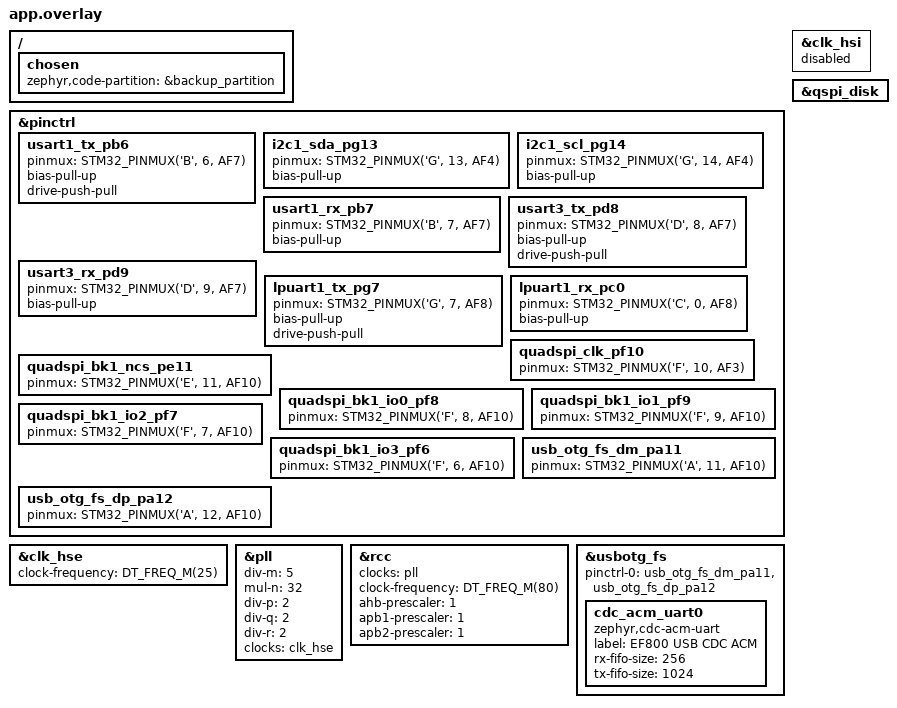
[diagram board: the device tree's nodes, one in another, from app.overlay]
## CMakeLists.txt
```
# SPDX-License-Identifier: Apache-2.0
cmake_minimum_required(VERSION 3.28.0)

set(BOARD_ROOT ${CMAKE_CURRENT_LIST_DIR}/../..)
set(DTS_ROOT ${CMAKE_CURRENT_LIST_DIR}/../..)
find_package(Zephyr REQUIRED HINTS $ENV{ZEPHYR_BASE})
project(ef800_backup)

target_sources(app PRIVATE
	src/main.c
	src/ef800_backup_composition.c
	src/ef800_backup_usb_mtp.c
	${CMAKE_CURRENT_LIST_DIR}/../../shared/ef800_composition/ef800_composition.c
	${CMAKE_CURRENT_LIST_DIR}/../../shared/ef800_persistence/ef800_persistence.c
	${CMAKE_CURRENT_LIST_DIR}/../../shared/ef800_watchdog/ef800_watchdog.c
	${CMAKE_CURRENT_LIST_DIR}/../../shared/ef800_storage/ef800_qspi_layout.c
	${CMAKE_CURRENT_LIST_DIR}/../../shared/ef800_lcd_contrast/ef800_lcd_contrast.c
	${CMAKE_CURRENT_LIST_DIR}/../../shared/ef800_lcd_contrast/ef800_lcd_contrast_storage.c
	${CMAKE_CURRENT_LIST_DIR}/../../shared/ef800_lcd_contrast/ef800_lcd_contrast_stm32.c
	${CMAKE_CURRENT_LIST_DIR}/../../shared/ef800_ports/ef800_console.c
	${CMAKE_CURRENT_LIST_DIR}/../../shared/ef800_ports/ef800_log_backend.c
	${CMAKE_CURRENT_LIST_DIR}/../../shared/ef800_update/ef800_update.c
)

target_include_directories(app PRIVATE
	${CMAKE_CURRENT_LIST_DIR}/../../shared/ef800_watchdog
	${CMAKE_CURRENT_LIST_DIR}/../../shared/ef800_ports
	${CMAKE_CURRENT_LIST_DIR}/../../shared/ef800_update
	${CMAKE_CURRENT_LIST_DIR}/../../shared/ef800_measurement
	${CMAKE_CURRENT_LIST_DIR}/../../shared/ef800_storage
	${CMAKE_CURRENT_LIST_DIR}/../../shared/ef800_lcd_contrast
	${CMAKE_CURRENT_LIST_DIR}/../../shared/ef800_composition
	${CMAKE_CURRENT_LIST_DIR}/../../shared/ef800_persistence
	${CMAKE_CURRENT_LIST_DIR}/src
)

target_include_directories(app PRIVATE
)
```

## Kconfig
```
# SPDX-License-Identifier: Apache-2.0

menu "EF800 backup recovery"

config EF800_USB_VID
	hex "Recovery USB vendor ID"
	default 0x2fe3
	help
	  Replace the development VID with the product VID before production.

config EF800_USB_PID
	hex "Recovery USB product ID"
	default 0xef80
	help
	  Product-specific PID for the EF800 recovery MTP device.

config EF800_USB_SELF_POWERED
	bool "Mark the recovery USB device as self-powered"
	default y
	help
	  Set the USB configuration self-powered attribute when the hardware is
	  powered independently of USB VBUS.

endmenu

source "Kconfig.zephyr"
```

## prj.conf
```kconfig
# SPDX-License-Identifier: Apache-2.0
CONFIG_FLASH=y
CONFIG_FLASH_MAP=y
CONFIG_FLASH_PAGE_LAYOUT=y
CONFIG_PINCTRL=y
CONFIG_GPIO=y
CONFIG_CLOCK_CONTROL=y
CONFIG_RESET=y
CONFIG_SERIAL=y
CONFIG_UART_USE_RUNTIME_CONFIGURE=y
CONFIG_LOG=y
CONFIG_LOG_BACKEND_UART=n
CONFIG_LOG_MODE_IMMEDIATE=y
CONFIG_WATCHDOG=y
CONFIG_IWDG_STM32_INITIAL_TIMEOUT=10000
CONFIG_DISK_DRIVERS=y
CONFIG_DISK_DRIVER_FLASH=y
CONFIG_FILE_SYSTEM=y
CONFIG_FAT_FILESYSTEM_ELM=y

CONFIG_USB_DEVICE_STACK_NEXT=y
CONFIG_USBD_MTP_CLASS=y
CONFIG_USBD_MTP_MAX_HANDLES=12
CONFIG_USBD_MTP_STORAGES_PER_INSTANCE=4
CONFIG_USBD_THREAD_STACK_SIZE=4096

CONFIG_EF800_USB_VID=0x2fe3
CONFIG_EF800_USB_PID=0xef80
# Recovery mode must remain within the expanded 128 KiB backup partition.
CONFIG_MAIN_STACK_SIZE=2048

# The recovery image occupies the fixed backup partition selected by app.overlay.
CONFIG_USE_DT_CODE_PARTITION=y
```

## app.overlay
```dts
/* SPDX-License-Identifier: Apache-2.0 */

/ {
	chosen {
		zephyr,code-partition = &backup_partition;
	};
};

#include <zephyr/dt-bindings/pinctrl/stm32-pinctrl.h>

&pinctrl {
	usart1_tx_pb6: usart1_tx_pb6 {
		pinmux = <STM32_PINMUX('B', 6, AF7)>;
		bias-pull-up;
		drive-push-pull;
	};

	i2c1_sda_pg13: i2c1_sda_pg13 {
		pinmux = <STM32_PINMUX('G', 13, AF4)>;
		bias-pull-up;
	};

	i2c1_scl_pg14: i2c1_scl_pg14 {
		pinmux = <STM32_PINMUX('G', 14, AF4)>;
		bias-pull-up;
	};

	usart1_rx_pb7: usart1_rx_pb7 {
		pinmux = <STM32_PINMUX('B', 7, AF7)>;
		bias-pull-up;
	};

	usart3_tx_pd8: usart3_tx_pd8 {
		pinmux = <STM32_PINMUX('D', 8, AF7)>;
		bias-pull-up;
		drive-push-pull;
	};

	usart3_rx_pd9: usart3_rx_pd9 {
		pinmux = <STM32_PINMUX('D', 9, AF7)>;
		bias-pull-up;
	};

	lpuart1_tx_pg7: lpuart1_tx_pg7 {
		pinmux = <STM32_PINMUX('G', 7, AF8)>;
		bias-pull-up;
		drive-push-pull;
	};

	lpuart1_rx_pc0: lpuart1_rx_pc0 {
		pinmux = <STM32_PINMUX('C', 0, AF8)>;
		bias-pull-up;
	};

	quadspi_clk_pf10: quadspi_clk_pf10 {
		pinmux = <STM32_PINMUX('F', 10, AF3)>;
	};

	quadspi_bk1_ncs_pe11: quadspi_bk1_ncs_pe11 {
		pinmux = <STM32_PINMUX('E', 11, AF10)>;
	};

	quadspi_bk1_io0_pf8: quadspi_bk1_io0_pf8 {
		pinmux = <STM32_PINMUX('F', 8, AF10)>;
	};

	quadspi_bk1_io1_pf9: quadspi_bk1_io1_pf9 {
		pinmux = <STM32_PINMUX('F', 9, AF10)>;
	};

	quadspi_bk1_io2_pf7: quadspi_bk1_io2_pf7 {
		pinmux = <STM32_PINMUX('F', 7, AF10)>;
	};

	quadspi_bk1_io3_pf6: quadspi_bk1_io3_pf6 {
		pinmux = <STM32_PINMUX('F', 6, AF10)>;
	};

	usb_otg_fs_dm_pa11: usb_otg_fs_dm_pa11 {
		pinmux = <STM32_PINMUX('A', 11, AF10)>;
	};

	usb_otg_fs_dp_pa12: usb_otg_fs_dp_pa12 {
		pinmux = <STM32_PINMUX('A', 12, AF10)>;
	};
};

&clk_hse {
	clock-frequency = <DT_FREQ_M(25)>;
	status = "okay";
};

&clk_hsi {
	status = "disabled";
};

&pll {
	div-m = <5>;
	mul-n = <32>;
	div-p = <2>;
	div-q = <2>;
	div-r = <2>;
	clocks = <&clk_hse>;
	status = "okay";
};

&rcc {
	clocks = <&pll>;
	clock-frequency = <DT_FREQ_M(80)>;
	ahb-prescaler = <1>;
	apb1-prescaler = <1>;
	apb2-prescaler = <1>;
};

&qspi_disk {
	status = "okay";
};

&usbotg_fs {
	pinctrl-0 = <&usb_otg_fs_dm_pa11 &usb_otg_fs_dp_pa12>;
	pinctrl-names = "default";
	status = "okay";

	cdc_acm_uart0: cdc_acm_uart0 {
		compatible = "zephyr,cdc-acm-uart";
		label = "EF800 USB CDC ACM";
		rx-fifo-size = <256>;
		tx-fifo-size = <1024>;
	};
};
```

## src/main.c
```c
/* SPDX-License-Identifier: Apache-2.0 */
/** @file @brief Run EF800 Backup recovery, storage, and USB services. */

#include <stdbool.h>
#include <errno.h>

#include <ff.h>
#include <zephyr/device.h>
#include <zephyr/devicetree.h>
#include <zephyr/fs/fs.h>
#include <zephyr/kernel.h>
#include <zephyr/logging/log.h>
#include <zephyr/storage/flash_map.h>

#include "ef800_watchdog.h"
#include "ef800_console.h"
#include "ef800_qspi_layout.h"
#include "ef800_backup_usb_mtp.h"
#include "ef800_backup_composition.h"
#include "ef800_lcd_contrast.h"
#include "ef800_lcd_contrast_storage.h"
#include "ef800_lcd_contrast_stm32.h"

LOG_MODULE_REGISTER(ef800_backup, LOG_LEVEL_INF);

#define EF800_BACKUP_CONFIGURATION_MOUNT "/EF800:"
#define EF800_BACKUP_DATA_MOUNT "/DATA:"

static K_THREAD_STACK_DEFINE(watchdog_stack, 512);
static struct k_thread watchdog_thread;
static FATFS configuration_fat_fs;
static FATFS data_fat_fs;
static struct fs_mount_t configuration_mount = {
	.type = FS_FATFS,
	.mnt_point = EF800_BACKUP_CONFIGURATION_MOUNT,
	.fs_data = &configuration_fat_fs,
	.storage_dev = (void *)PARTITION_ID(qspi_configuration_partition),
	.flags = FS_MOUNT_FLAG_NO_FORMAT,
};
static struct fs_mount_t data_mount = {
	.type = FS_FATFS,
	.mnt_point = EF800_BACKUP_DATA_MOUNT,
	.fs_data = &data_fat_fs,
	.storage_dev = (void *)PARTITION_ID(qspi_storage_partition),
	.flags = FS_MOUNT_FLAG_NO_FORMAT,
};
static struct ef800_lcd_contrast lcd_contrast;

static int backup_contrast_set_pwm(void *context, uint8_t duty_percent)
{
	ARG_UNUSED(context);
	return ef800_lcd_contrast_stm32_set(duty_percent);
}

static void backup_contrast_diagnostic(void *context, const char *message,
				       int error)
{
	ARG_UNUSED(context);
	LOG_WRN("%s: %d", message, error);
}

static const struct ef800_lcd_contrast_ops backup_contrast_ops = {
	.load_duty = ef800_lcd_contrast_storage_load_duty,
	.save_duty = ef800_lcd_contrast_storage_save_duty,
	.set_pwm = backup_contrast_set_pwm,
	.diagnostic = backup_contrast_diagnostic,
};

static void backup_watchdog_task(void *arg1, void *arg2, void *arg3)
{
	ARG_UNUSED(arg1);
	ARG_UNUSED(arg2);
	ARG_UNUSED(arg3);

	while (true) {
		(void)ef800_watchdog_feed();
		k_msleep(250U);
	}
}

static void backup_watchdog_start(void)
{
	if (ef800_watchdog_start(1000U) != 0) {
		return;
	}
	(void)k_thread_create(&watchdog_thread, watchdog_stack,
				      K_THREAD_STACK_SIZEOF(watchdog_stack),
				      backup_watchdog_task, NULL, NULL, NULL,
				      K_PRIO_PREEMPT(2), 0, K_NO_WAIT);
}
#define EF800_USB_UDC_NODE DT_NODELABEL(usbotg_fs)

BUILD_ASSERT(DT_NODE_HAS_STATUS(EF800_USB_UDC_NODE, okay),
		     "EF800 recovery requires an enabled USB device controller");

static int ensure_directory(const char *path)
{
	struct fs_dirent entry;
	int ret = fs_stat(path, &entry);

	if (ret == 0) {
		return entry.type == FS_DIR_ENTRY_DIR ? 0 : -ENOTDIR;
	}
	ret = fs_mkdir(path);
	return ret == -EEXIST ? 0 : ret;
}

static int create_recovery_roots(void)
{
	static const char *const paths[] = {
		"/EF800:/.configuration",
		"/DATA:/data",
		"/DATA:/plugins",
		"/DATA:/fwu",
	};

	for (size_t index = 0U; index < ARRAY_SIZE(paths); ++index) {
		int ret = ensure_directory(paths[index]);

		if (ret != 0) {
			LOG_ERR("Cannot prepare MTP root %s: %d", paths[index], ret);
			return ret;
		}
	}
	return 0;
}

int main(void)
{
	const struct device *const udc = DEVICE_DT_GET(EF800_USB_UDC_NODE);
	const struct flash_area *boot_state_area;
	bool legacy_layout;
	bool configuration_mounted = false;
	bool data_mounted = false;
	int ret;

	(void)ef800_console_init(true);
	printk("ef800 backup application: console=%u\r\n",
	       ef800_console_get_target());
	backup_watchdog_start();

	if (!device_is_ready(udc)) {
		LOG_ERR("USB device controller unavailable; recovery MTP not started");
		goto wait;
	}
	ret = flash_area_open(PARTITION_ID(qspi_bootstate_partition),
		&boot_state_area);
	if (ret != 0) {
		LOG_ERR("Boot-state QSPI partition unavailable: %d", ret);
		goto wait;
	}
	ret = ef800_qspi_layout_check_legacy_area(boot_state_area, &legacy_layout);
	flash_area_close(boot_state_area);
	if (ret != 0 || legacy_layout) {
		LOG_ERR("Legacy or unavailable QSPI layout; recovery MTP not started: %d",
			ret != 0 ? ret : -ENOTSUP);
		goto wait;
	}
	ret = fs_mount(&configuration_mount);
	if (ret != 0) {
		LOG_ERR("Configuration FAT mount failed (no format attempted): %d", ret);
		goto wait;
	}
	configuration_mounted = true;
	ret = fs_mount(&data_mount);
	if (ret != 0) {
		LOG_ERR("Shared-data FAT mount failed (no format attempted): %d", ret);
		goto cleanup;
	}
	data_mounted = true;
	ret = create_recovery_roots();
	if (ret != 0) {
		goto cleanup;
	}
	{
		enum ef800_lcd_contrast_mode mode;

		ret = ef800_backup_composition_lcd_contrast_mode(&mode);
		if (ret == 0) {
			ret = ef800_lcd_contrast_init(&lcd_contrast, mode,
				&backup_contrast_ops, NULL);
		}
		if (ret != 0) {
			LOG_WRN("Backup LCD contrast initialization failed: %d", ret);
		}
	}
	ret = ef800_backup_usb_mtp_start();
	if (ret != 0) {
		LOG_ERR("Recovery MTP start failed: %d", ret);
		goto cleanup;
	}
	LOG_INF("Backup recovery MTP active: Configuration, Data, Plugins, FWU");
	goto wait;

cleanup:
	if (data_mounted) {
		(void)fs_unmount(&data_mount);
	}
	if (configuration_mounted) {
		(void)fs_unmount(&configuration_mount);
	}

wait:
	while (true) {
		k_sleep(K_FOREVER);
	}
}
```

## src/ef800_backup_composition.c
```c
/* SPDX-License-Identifier: Apache-2.0 */

#include "ef800_backup_composition.h"

#include <errno.h>
#include <string.h>

#include <ff.h>
#include <zephyr/fs/fs.h>
#include <zephyr/kernel.h>
#include <zephyr/logging/log.h>

#include "ef800_composition.h"

LOG_MODULE_REGISTER(ef800_backup_composition, LOG_LEVEL_INF);

#define EF800_BACKUP_COMPOSITION_PATH "/EF800:/.configuration/"

struct backup_composition_candidate {
	struct ef800_composition_profile profile;
	bool valid;
	int error;
};

static const struct ef800_composition_catalog_entry lcd_contrast_entries[] = {
	{ "LCDCONTR0", "LCDCONTR", EF800_LCD_CONTRAST_STATIC, true, true },
	{ "LCDCONTR1", "LCDCONTR", EF800_LCD_CONTRAST_PWM, false, true },
};
static const struct ef800_composition_catalog lcd_contrast_catalog = {
	.entries = lcd_contrast_entries,
	.entry_count = ARRAY_SIZE(lcd_contrast_entries),
};
static uint8_t composition_record[EF800_COMPOSITION_RECORD_MAX + 1U];
static struct backup_composition_candidate candidates[2];
static struct ef800_composition_snapshot resolved_snapshot;

static int read_candidate(const char *name,
			 struct backup_composition_candidate *candidate)
{
	struct fs_file_t file;
	struct fs_dirent entry;
	char path[96];
	ssize_t length;
	int ret;

	*candidate = (struct backup_composition_candidate){0};
	ret = snprintk(path, sizeof(path), "%s%s", EF800_BACKUP_COMPOSITION_PATH,
		name);
	if (ret < 0 || (size_t)ret >= sizeof(path)) {
		candidate->error = -ENAMETOOLONG;
		return candidate->error;
	}
	ret = fs_stat(path, &entry);
	if (ret != 0) {
		candidate->error = ret;
		return ret;
	}
	if (entry.type != FS_DIR_ENTRY_FILE) {
		candidate->error = -EISDIR;
		return candidate->error;
	}
	if (entry.size > EF800_COMPOSITION_RECORD_MAX) {
		candidate->error = -E2BIG;
		return candidate->error;
	}
	fs_file_t_init(&file);
	ret = fs_open(&file, path, FS_O_READ);
	if (ret != 0) {
		candidate->error = ret;
		return ret;
	}
	length = fs_read(&file, composition_record, sizeof(composition_record));
	ret = fs_close(&file);
	if (length < 0) {
		candidate->error = (int)length;
		return candidate->error;
	}
	if (ret != 0) {
		candidate->error = ret;
		return ret;
	}
	if ((size_t)length != entry.size) {
		candidate->error = -EIO;
		return candidate->error;
	}
	ret = ef800_composition_profile_decode(composition_record, (size_t)length,
		&candidate->profile);
	candidate->error = ret;
	candidate->valid = ret == 0;
	return ret;
}

int ef800_backup_composition_lcd_contrast_mode(
	enum ef800_lcd_contrast_mode *mode)
{
	static const char *const slot_names[] = {
		EF800_COMPOSITION_SLOT_A,
		EF800_COMPOSITION_SLOT_B,
	};
	struct ef800_composition_profile selected = {0};
	int selected_slot = -1;
	int ret;

	if (mode == NULL) {
		return -EINVAL;
	}
	*mode = EF800_LCD_CONTRAST_STATIC;
	for (size_t index = 0U; index < ARRAY_SIZE(candidates); ++index) {
		(void)read_candidate(slot_names[index], &candidates[index]);
	}
	ret = ef800_composition_profile_select(&candidates[0].profile,
		candidates[0].valid, &candidates[1].profile, candidates[1].valid,
		&selected, &selected_slot);
	if (ret == -EBADMSG) {
		LOG_WRN("Composition slots conflict; using LCDCONTR0 default");
	} else if (ret != 0 && ret != -ENOENT) {
		LOG_WRN("Composition slots unavailable; using LCDCONTR0 default: %d", ret);
	}
	ret = ef800_composition_resolve(&selected, &lcd_contrast_catalog,
		&resolved_snapshot);
	if (ret != 0) {
		LOG_WRN("LCD contrast composition invalid; using LCDCONTR0 default: %d", ret);
		return 0;
	}
	for (size_t index = 0U; index < resolved_snapshot.effective_count; ++index) {
		const struct ef800_composition_catalog_entry *entry =
			resolved_snapshot.effective[index].catalog_entry;

		if (entry != NULL && strcmp(entry->group, "LCDCONTR") == 0) {
			*mode = entry->selection == EF800_LCD_CONTRAST_PWM ?
				EF800_LCD_CONTRAST_PWM : EF800_LCD_CONTRAST_STATIC;
			return 0;
		}
	}
	return 0;
}
```

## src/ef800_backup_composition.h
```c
/* SPDX-License-Identifier: Apache-2.0 */
/** @file
 * @brief Read composition-backed LCD contrast mode for EF800 Backup.
 */
#ifndef EF800_BACKUP_COMPOSITION_H_
#define EF800_BACKUP_COMPOSITION_H_

#include "ef800_lcd_contrast.h"

/** @brief Resolve the effective LCD contrast mode from the active composition.
 * @param mode Receives the selected mode on success.
 * @return 0 on success; negative errno if composition data is unavailable/invalid.
 */
int ef800_backup_composition_lcd_contrast_mode(
	enum ef800_lcd_contrast_mode *mode);

#endif /* EF800_BACKUP_COMPOSITION_H_ */
```

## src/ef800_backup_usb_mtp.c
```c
/* SPDX-License-Identifier: Apache-2.0 */

#include "ef800_backup_usb_mtp.h"

#include <errno.h>

#include <zephyr/device.h>
#include <zephyr/devicetree.h>
#include <zephyr/usb/class/usbd_mtp.h>
#include <zephyr/usb/usbd.h>

#define EF800_BACKUP_USB_UDC_NODE DT_NODELABEL(usbotg_fs)

BUILD_ASSERT(DT_NODE_HAS_STATUS(EF800_BACKUP_USB_UDC_NODE, okay),
	"EF800 Backup recovery MTP requires the fitted USB controller");

USBD_DEVICE_DEFINE(ef800_backup_mtp_usbd,
	DEVICE_DT_GET(EF800_BACKUP_USB_UDC_NODE),
	CONFIG_EF800_USB_VID, CONFIG_EF800_USB_PID);
USBD_DESC_LANG_DEFINE(ef800_backup_mtp_lang);
USBD_DESC_MANUFACTURER_DEFINE(ef800_backup_mtp_manufacturer, "EF800");
USBD_DESC_PRODUCT_DEFINE(ef800_backup_mtp_product, "EF800 Recovery");
USBD_DESC_CONFIG_DEFINE(ef800_backup_mtp_config_desc, "EF800 Recovery MTP");

USBD_CONFIGURATION_DEFINE(ef800_backup_mtp_config,
	(IS_ENABLED(CONFIG_EF800_USB_SELF_POWERED) ? USB_SCD_SELF_POWERED : 0U),
	125, &ef800_backup_mtp_config_desc);

USBD_MTP_DEFINE_INSTANCE(ef800_backup,
	"EF800", "EF800 Recovery", "1.0", "EF800000000000000000000000000002",
	USBD_MTP_STORAGE_ENTRY_NAMED("/EF800:/.configuration", "Configuration", false),
	USBD_MTP_STORAGE_ENTRY_NAMED("/DATA:/data", "Data", false),
	USBD_MTP_STORAGE_ENTRY_NAMED("/DATA:/plugins", "Plugins", false),
	USBD_MTP_STORAGE_ENTRY_NAMED("/DATA:/fwu", "FWU", false));

static bool mtp_configured;
static bool mtp_active;

static void configure_mtp_device_descriptor(void)
{
	/* Keep this a single MTP/PTP interface for desktop MTP host compatibility. */
	fs_desc_ef800_backup_mtp_usbd.bDeviceClass = 0;
	fs_desc_ef800_backup_mtp_usbd.bDeviceSubClass = 0;
	fs_desc_ef800_backup_mtp_usbd.bDeviceProtocol = 0;
	fs_desc_ef800_backup_mtp_usbd.bMaxPacketSize0 = 64;
#if USBD_SUPPORTS_HIGH_SPEED
	hs_desc_ef800_backup_mtp_usbd.bDeviceClass = 0;
	hs_desc_ef800_backup_mtp_usbd.bDeviceSubClass = 0;
	hs_desc_ef800_backup_mtp_usbd.bDeviceProtocol = 0;
	hs_desc_ef800_backup_mtp_usbd.bMaxPacketSize0 = 64;
#endif
}

int ef800_backup_usb_mtp_start(void)
{
	int ret;

	if (mtp_active) {
		return 0;
	}
	configure_mtp_device_descriptor();
	if (!mtp_configured) {
		ret = usbd_add_descriptor(&ef800_backup_mtp_usbd, &ef800_backup_mtp_lang);
		if (ret != 0) {
			return ret;
		}
		ret = usbd_add_descriptor(&ef800_backup_mtp_usbd,
			&ef800_backup_mtp_manufacturer);
		if (ret != 0) {
			return ret;
		}
		ret = usbd_add_descriptor(&ef800_backup_mtp_usbd, &ef800_backup_mtp_product);
		if (ret != 0) {
			return ret;
		}
		ret = usbd_add_configuration(&ef800_backup_mtp_usbd, USBD_SPEED_FS,
			&ef800_backup_mtp_config);
		if (ret != 0) {
			return ret;
		}
		mtp_configured = true;
	}
	ret = usbd_register_all_classes(&ef800_backup_mtp_usbd, USBD_SPEED_FS,
		1, NULL);
	if (ret != 0) {
		return ret;
	}
	ret = usbd_init(&ef800_backup_mtp_usbd);
	if (ret != 0) {
		return ret;
	}
	ret = usbd_enable(&ef800_backup_mtp_usbd);
	if (ret == 0) {
		mtp_active = true;
	}
	return ret;
}

int ef800_backup_usb_mtp_stop(void)
{
	int ret;

	if (!mtp_active) {
		return 0;
	}
	ret = usbd_disable(&ef800_backup_mtp_usbd);
	if (ret != 0 && ret != -EALREADY) {
		return ret;
	}
	ret = usbd_shutdown(&ef800_backup_mtp_usbd);
	if (ret == 0) {
		mtp_active = false;
	}
	return ret;
}

bool ef800_backup_usb_mtp_is_active(void)
{
	return mtp_active;
}
```

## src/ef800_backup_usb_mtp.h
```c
/* SPDX-License-Identifier: Apache-2.0 */
/** @file
 * @brief Start, stop, and query EF800 Backup USB MTP service state.
 */
#ifndef EF800_BACKUP_USB_MTP_H_
#define EF800_BACKUP_USB_MTP_H_

#include <stdbool.h>

/** @brief Start the USB MTP service.
 * @return 0 on success; negative errno if initialization or enablement fails.
 */
int ef800_backup_usb_mtp_start(void);

/** @brief Stop the USB MTP service.
 * @return 0 on success; negative errno if the service cannot be disabled.
 */
int ef800_backup_usb_mtp_stop(void);

/** @brief Check whether the USB MTP service is active.
 * @return True when MTP is enabled, otherwise false.
 */
bool ef800_backup_usb_mtp_is_active(void);

#endif /* EF800_BACKUP_USB_MTP_H_ */
```
